# V3s register map
Vendor: Allwinner; Series: V3s; File version: 0.1
CPU: ARM Cortex-A7 MP1 0, little endian, MPU, no FPU, 0 interrupt priority bits
Registers are 32-bit, read-write, reset 0x0 unless marked. A register's access mark holds for its fields unless they carry their own. Offsets are from the block's base; [hi:lo] are bit positions; 'fields as' and 'values as' point back to an identical list.

## LRADC
Base 0x01C22800
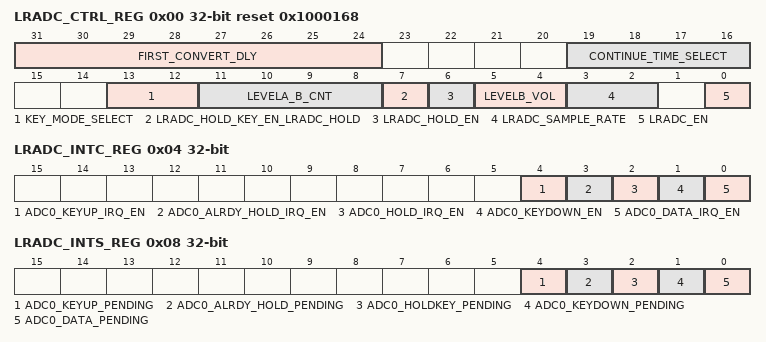
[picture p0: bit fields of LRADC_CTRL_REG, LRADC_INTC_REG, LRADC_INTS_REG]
0x00 LRADC_CTRL_REG reset 0x1000168
  [31:24] FIRST_CONVERT_DLY — FIRST_CONVERT_DLY. ADC First Convert Delay setting, ADC conversion is delayed by n samples
  [19:16] CONTINUE_TIME_SELECT — CONTINUE_TIME_SELECT. Continue Mode time select, one of 8*(N+1) sample as a valuable sample data
  [13:12] KEY_MODE_SELECT — KEY_MODE_SELECT. Key Mode Select: 00: Normal Mode 01: Single Mode 10: Continue Mode
    0=Normal Mode; 1=Single Mode; 2=Continue Mode
  [11:8] LEVELA_B_CNT — LEVELA_B_CNT. Level A to Level B time threshold select, judge ADC convert value in level A to level B in n+1 samples
  [7] LRADC_HOLD_KEY_EN_LRADC_HOLD — LRADC_HOLD_KEY_EN LRADC Hold Key Enable 0: Disable 1: Enable
    0=Disable; 1=Enable
  [6] LRADC_HOLD_EN — LRADC_HOLD_EN. LRADC Sample hold Enable 0: Disable 1: Enable
    0=Disable; 1=Enable
  [5:4] LEVELB_VOL — LEVELB_VOL. Level B Corresponding Data Value setting (the real voltage value) 00: 0x3C (~1.9v) 01: 0x39 (~1.8v) 10: 0x36 (~1.7v) 11: 0x33 (~1.6v)
    0=0x3C (~1.9v); 1=0x39 (~1.8v); 2=0x36 (~1.7v); 3=0x33 (~1.6v)
  [3:2] LRADC_SAMPLE_RATE — LRADC_SAMPLE_RATE. LRADC Sample Rate 00: 250 Hz 01: 125 Hz 10: 62.5 Hz 11: 32.25 Hz
    0=250 Hz; 1=125 Hz; 2=_62_point_5 (62.5 Hz); 3=_32_point_25 (32.25 Hz)
  [0] LRADC_EN — LRADC_EN. LRADC enable 0: Disable 1: Enable
    0=Disable; 1=Enable
0x04 LRADC_INTC_REG
  [all] fields
    0=Disable; 1=Enable
  [4] ADC0_KEYUP_IRQ_EN — ADC0 Key Up IRQ Enable 0: Disable 1: Enable
  [3] ADC0_ALRDY_HOLD_IRQ_EN — ADC0 Already Hold IRQ Enable 0: Disable 1: Enable
  [2] ADC0_HOLD_IRQ_EN — ADC0 Hold Key IRQ Enable 0: Disable 1: Enable
  [1] ADC0_KEYDOWN_EN — ADC0 Key Down Enable 0: Disable 1: Enable
  [0] ADC0_DATA_IRQ_EN — ADC0 Data IRQ Enable 0: Disable 1: Enable
0x08 LRADC_INTS_REG
  [4] ADC0_KEYUP_PENDING — ADC0 Key up Pending Bit When general key pull up, it the corresponding interrupt is enabled. 0: No IRQ 1: IRQ Pending Notes: Writing 1 to the bit will clear it and its corresponding interrupt if the interrupt is enable
    0=No_IRQ; 1=IRQ (IRQ Pending Notes: Writing 1 to the bit will clear it and its corresponding interrupt if the interrupt is enable)
  [3] ADC0_ALRDY_HOLD_PENDING — ADC0 Already Hold Pending Bit When hold key pull down and pull the general key down, if the corresponding interrupt is enabled. 0: No IRQ 1: IRQ Pending Notes: Writing 1 to the bit will clear it and its corresponding interrupt if the interrupt is enable
    values as ADC0_KEYUP_PENDING
  [2] ADC0_HOLDKEY_PENDING — ADC0 Hold Key Pending Bit When Hold key pull down, the status bit is set and the interrupt line is set if the corresponding interrupt is enabled. 0: NO IRQ 1: IRQ Pending Notes: Writing 1 to the bit will clear it and its corresponding interrupt if the interrupt is enable.
    0=NO_IRQ; 1=IRQ (IRQ Pending Notes: Writing 1 to the bit will clear it and its corresponding interrupt if the interrupt is enable.)
  [1] ADC0_KEYDOWN_PENDING — ADC0 Key Down IRQ Pending Bit When General key pull down, the status bit is set and the interrupt line is set if the corresponding interrupt is enabled. 0: No IRQ 1: IRQ Pending Notes: Writing 1 to the bit will clear it and its corresponding interrupt if the interrupt is enable.
    0=No_IRQ; 1=IRQ (IRQ Pending Notes: Writing 1 to the bit will clear it and its corresponding interrupt if the interrupt is enable.)
  [0] ADC0_DATA_PENDING — ADC0 Data IRQ Pending Bit 0: No IRQ 1: IRQ Pending Notes: Writing 1 to the bit will clear it and its corresponding interrupt if the interrupt is enable.
    values as ADC0_KEYDOWN_PENDING
0x0C LRADC_DATA0_REG
  [5:0] LRADC_DATA0 ro
